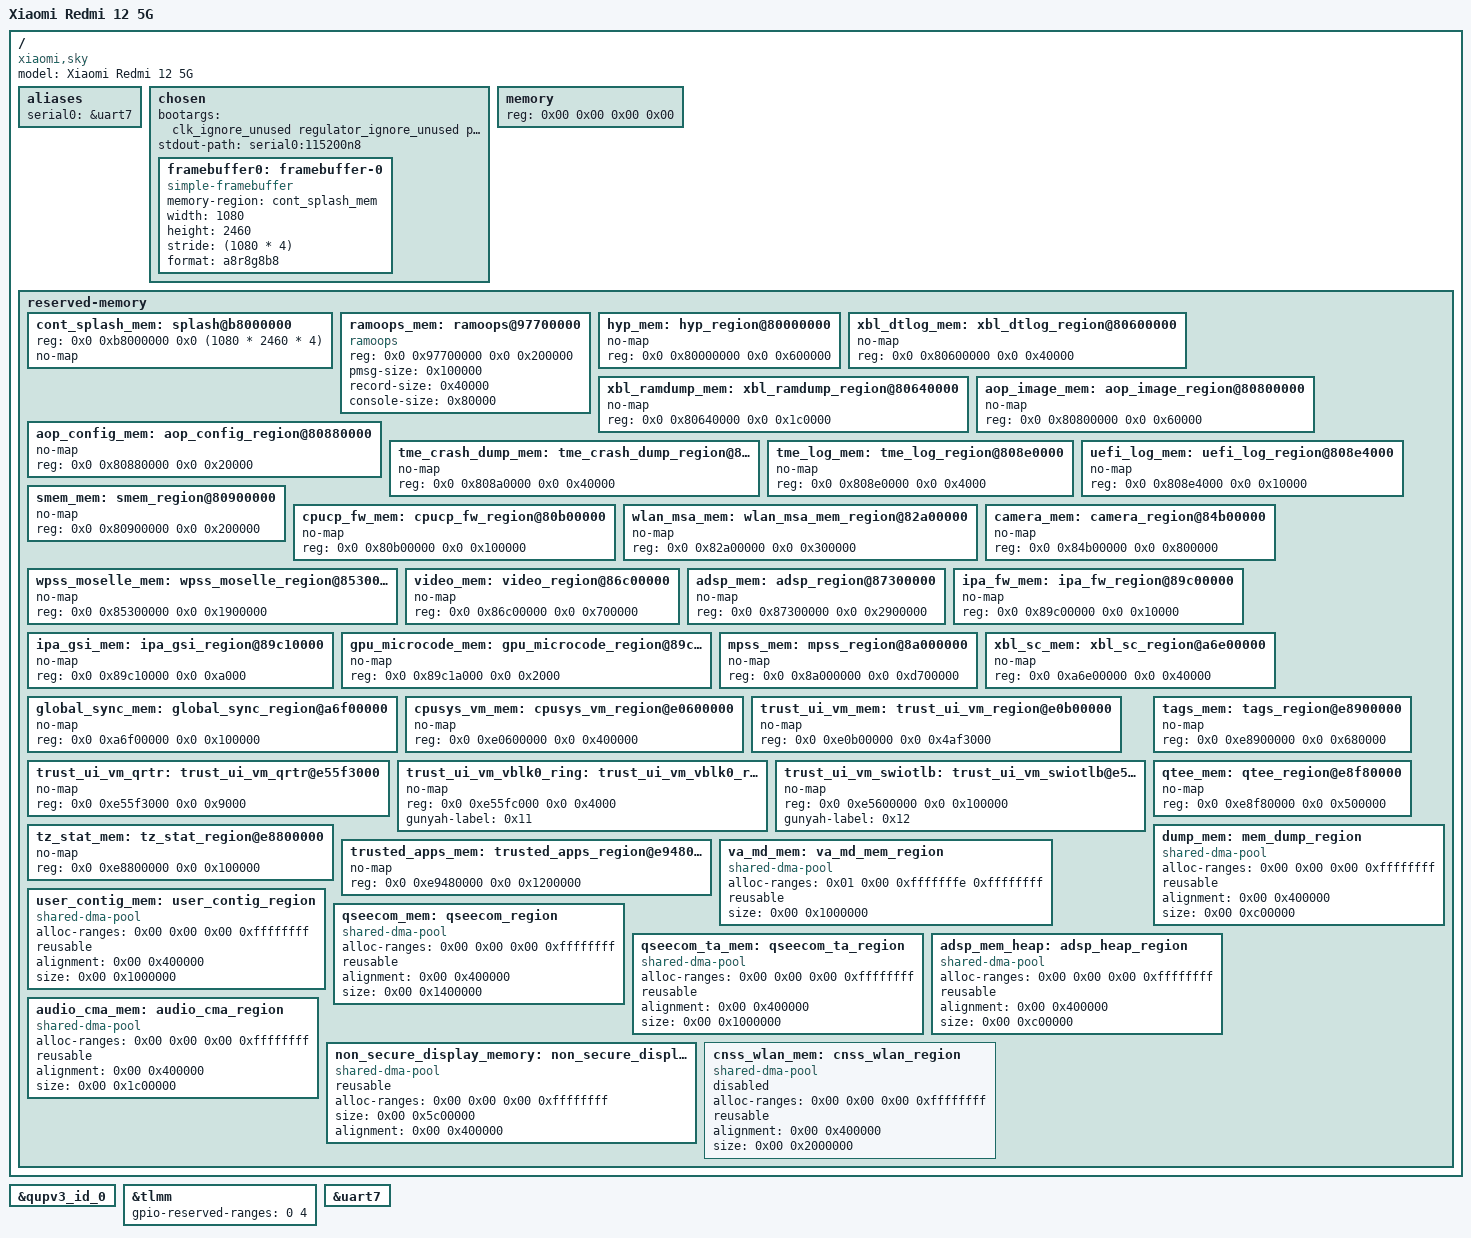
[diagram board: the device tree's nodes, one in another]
// SPDX-License-Identifier: BSD-3-Clause
/*
 * Copyright (c) 2026 Trijal Saha - <trijalsaha2012@gmail.com>
 */

/dts-v1/;

#include "sm4450.dtsi"
/ {
	model = "Xiaomi Redmi 12 5G";
	compatible = "xiaomi,sky", "qcom,sm4450";

	aliases {
		serial0 = &uart7;
	};

	chosen {
		bootargs = "clk_ignore_unused regulator_ignore_unused pd_ignore_unused earlycon=qcom_geni,0x00a88000";
		stdout-path = "serial0:115200n8";

		/* Use display framebuffer as setup by bootloader */
		framebuffer0: framebuffer-0 {
			compatible = "simple-framebuffer";
			memory-region = <&cont_splash_mem>;
			width = <1080>;
			height = <2460>;
			stride = <(1080 * 4)>;
			format = "a8r8g8b8";
			status = "okay";
		};
	};

	memory {
		device_type = "memory";
		reg = <0x00 0x00 0x00 0x00>;
	};

	// memory@80000000 {
	// 	device_type = "memory";
	// 	reg = <0x00 0x80000000 0x00 0x68e00000>;
	// };
 //
	// memory@e9500000 {
	// 	device_type = "memory";
	// 	reg = <0x00 0xe9500000 0x00 0x00000000>;
	// };
 //
	// memory@f1300000 {
	// 	device_type = "memory";
	// 	reg = <0x00 0xf1300000 0x00 0x0ed00000>;
	// };
 //
	// memory@800000000 {
	// 	device_type = "memory";
	// 	reg = <0x08 0x00000000 0x00 0x3fc00000>;
	// };
 //
	// memory@880000000 {
	// 	device_type = "memory";
	// 	reg = <0x08 0x80000000 0x00 0x3b300000>;
	// };
 //
	// memory@840000000 {
	// 	device_type = "memory";
	// 	reg = <0x08 0x40000000 0x00 0x40000000>;
	// };
 //
	// memory@8c0000000 {
	// 	device_type = "memory";
	// 	reg = <0x08 0xc0000000 0x00 0xc0000000>;
	// };
 //
	// memory@8bb900000 {
	// 	device_type = "memory";
	// 	reg = <0x08 0xbb900000 0x00 0x01e00000>;
	// };

	reserved-memory {
		/* Bootloader Contiguous Framebuffer Memory Region */
		cont_splash_mem: splash@b8000000 {
			reg = <0x0 0xb8000000 0x0 (1080 * 2460 * 4)>;
			no-map;
		};

		/* PStore Ramoops Memory Region for Logs */
		ramoops_mem: ramoops@97700000 {
			compatible = "ramoops";
			reg = <0x0 0x97700000 0x0 0x200000>;
			pmsg-size = <0x100000>;
			record-size = <0x40000>;
			console-size = <0x80000>;
		};

		/* PROPRIETARY RESERVED NODES BEGIN */
		hyp_mem: hyp_region@80000000 {
			no-map;
			reg = <0x0 0x80000000 0x0 0x600000>;
		};

		xbl_dtlog_mem: xbl_dtlog_region@80600000 {
			no-map;
			reg = <0x0 0x80600000 0x0 0x40000>;
		};

		xbl_ramdump_mem: xbl_ramdump_region@80640000 {
			no-map;
			reg = <0x0 0x80640000 0x0 0x1c0000>;
		};

		aop_image_mem: aop_image_region@80800000 {
			no-map;
			reg = <0x0 0x80800000 0x0 0x60000>;
		};

		// aop_cmd_db_mem: aop_cmd_db_region@80860000 {
		// 	compatible = "qcom,cmd-db";
		// 	no-map;
		// 	reg = <0x0 0x80860000 0x0 0x20000>;
		// };

		aop_config_mem: aop_config_region@80880000 {
			no-map;
			reg = <0x0 0x80880000 0x0 0x20000>;
		};

		tme_crash_dump_mem: tme_crash_dump_region@808a0000 {
			no-map;
			reg = <0x0 0x808a0000 0x0 0x40000>;
		};

		tme_log_mem: tme_log_region@808e0000 {
			no-map;
			reg = <0x0 0x808e0000 0x0 0x4000>;
		};

		uefi_log_mem: uefi_log_region@808e4000 {
			no-map;
			reg = <0x0 0x808e4000 0x0 0x10000>;
		};

		smem_mem: smem_region@80900000 {
			no-map;
			reg = <0x0 0x80900000 0x0 0x200000>;
		};

		cpucp_fw_mem: cpucp_fw_region@80b00000 {
			no-map;
			reg = <0x0 0x80b00000 0x0 0x100000>;
		};

		wlan_msa_mem: wlan_msa_mem_region@82a00000 {
			no-map;
			reg = <0x0 0x82a00000 0x0 0x300000>;
		};

		camera_mem: camera_region@84b00000 {
			no-map;
			reg = <0x0 0x84b00000 0x0 0x800000>;
		};

		wpss_moselle_mem: wpss_moselle_region@85300000 {
			no-map;
			reg = <0x0 0x85300000 0x0 0x1900000>;
		};

		video_mem: video_region@86c00000 {
			no-map;
			reg = <0x0 0x86c00000 0x0 0x700000>;
		};

		adsp_mem: adsp_region@87300000 {
			no-map;
			reg = <0x0 0x87300000 0x0 0x2900000>;
		};

		ipa_fw_mem: ipa_fw_region@89c00000 {
			no-map;
			reg = <0x0 0x89c00000 0x0 0x10000>;
		};

		ipa_gsi_mem: ipa_gsi_region@89c10000 {
			no-map;
			reg = <0x0 0x89c10000 0x0 0xa000>;
		};

		gpu_microcode_mem: gpu_microcode_region@89c1a000 {
			no-map;
			reg = <0x0 0x89c1a000 0x0 0x2000>;
		};

		mpss_mem: mpss_region@8a000000 {
			no-map;
			reg = <0x0 0x8a000000 0x0 0xd700000>;
		};

		xbl_sc_mem: xbl_sc_region@a6e00000 {
			no-map;
			reg = <0x0 0xa6e00000 0x0 0x40000>;
		};

		global_sync_mem: global_sync_region@a6f00000 {
			no-map;
			reg = <0x0 0xa6f00000 0x0 0x100000>;
		};

		cpusys_vm_mem: cpusys_vm_region@e0600000 {
			no-map;
			reg = <0x0 0xe0600000 0x0 0x400000>;
		};

		trust_ui_vm_mem: trust_ui_vm_region@e0b00000 {
			no-map;
			reg = <0x0 0xe0b00000 0x0 0x4af3000>;
		};

		trust_ui_vm_qrtr: trust_ui_vm_qrtr@e55f3000 {
			no-map;
			reg = <0x0 0xe55f3000 0x0 0x9000>;
		};

		trust_ui_vm_vblk0_ring: trust_ui_vm_vblk0_ring@e55fc000 {
			no-map;
			reg = <0x0 0xe55fc000 0x0 0x4000>;
			gunyah-label = <0x11>;
		};

		trust_ui_vm_swiotlb: trust_ui_vm_swiotlb@e5600000 {
			no-map;
			reg = <0x0 0xe5600000 0x0 0x100000>;
			gunyah-label = <0x12>;
		};

		tz_stat_mem: tz_stat_region@e8800000 {
			no-map;
			reg = <0x0 0xe8800000 0x0 0x100000>;
		};

		tags_mem: tags_region@e8900000 {
			no-map;
			reg = <0x0 0xe8900000 0x0 0x680000>;
		};

		qtee_mem: qtee_region@e8f80000 {
			no-map;
			reg = <0x0 0xe8f80000 0x0 0x500000>;
		};

		trusted_apps_mem: trusted_apps_region@e9480000 {
			no-map;
			reg = <0x0 0xe9480000 0x0 0x1200000>;
		};

		dump_mem: mem_dump_region {
			compatible = "shared-dma-pool";
			alloc-ranges = <0x00 0x00 0x00 0xffffffff>;
			reusable;
			alignment = <0x00 0x400000>;
			size = <0x00 0xc00000>;
		};

		// system_cma: linux,cma {
		// 	compatible = "shared-dma-pool";
		// 	alloc-ranges = <0x00 0x00 0x00 0xffffffff>;
		// 	reusable;
		// 	alignment = <0x00 0x400000>;
		// 	size = <0x00 0x2000000>;
		// 	linux,cma-default;
		// };

		va_md_mem: va_md_mem_region {
			compatible = "shared-dma-pool";
			alloc-ranges = <0x01 0x00 0xfffffffe 0xffffffff>;
			reusable;
			size = <0x00 0x1000000>;
		};

		user_contig_mem: user_contig_region {
			compatible = "shared-dma-pool";
			alloc-ranges = <0x00 0x00 0x00 0xffffffff>;
			reusable;
			alignment = <0x00 0x400000>;
			size = <0x00 0x1000000>;
		};

		qseecom_mem: qseecom_region {
			compatible = "shared-dma-pool";
			alloc-ranges = <0x00 0x00 0x00 0xffffffff>;
			reusable;
			alignment = <0x00 0x400000>;
			size = <0x00 0x1400000>;
		};

		qseecom_ta_mem: qseecom_ta_region {
			compatible = "shared-dma-pool";
			alloc-ranges = <0x00 0x00 0x00 0xffffffff>;
			reusable;
			alignment = <0x00 0x400000>;
			size = <0x00 0x1000000>;
		};

		adsp_mem_heap: adsp_heap_region {
			compatible = "shared-dma-pool";
			alloc-ranges = <0x00 0x00 0x00 0xffffffff>;
			reusable;
			alignment = <0x00 0x400000>;
			size = <0x00 0xc00000>;
		};

		audio_cma_mem: audio_cma_region {
			compatible = "shared-dma-pool";
			alloc-ranges = <0x00 0x00 0x00 0xffffffff>;
			reusable;
			alignment = <0x00 0x400000>;
			size = <0x00 0x1c00000>;
		};

		non_secure_display_memory: non_secure_display_region {
			compatible = "shared-dma-pool";
			reusable;
			alloc-ranges = <0x00 0x00 0x00 0xffffffff>;
			size = <0x00 0x5c00000>;
			alignment = <0x00 0x400000>;
		};

		cnss_wlan_mem: cnss_wlan_region {
			compatible = "shared-dma-pool";
			alloc-ranges = <0x00 0x00 0x00 0xffffffff>;
			reusable;
			alignment = <0x00 0x400000>;
			size = <0x00 0x2000000>;
			status = "disabled";
		};
		/* PROPRIETARY RESERVED NODES END */
	};
};

&qupv3_id_0 {
	status = "okay";
};

&tlmm {
	gpio-reserved-ranges = <0 4>; /* NFC eSE SPI */
};

&uart7 {
	status = "okay";
};
